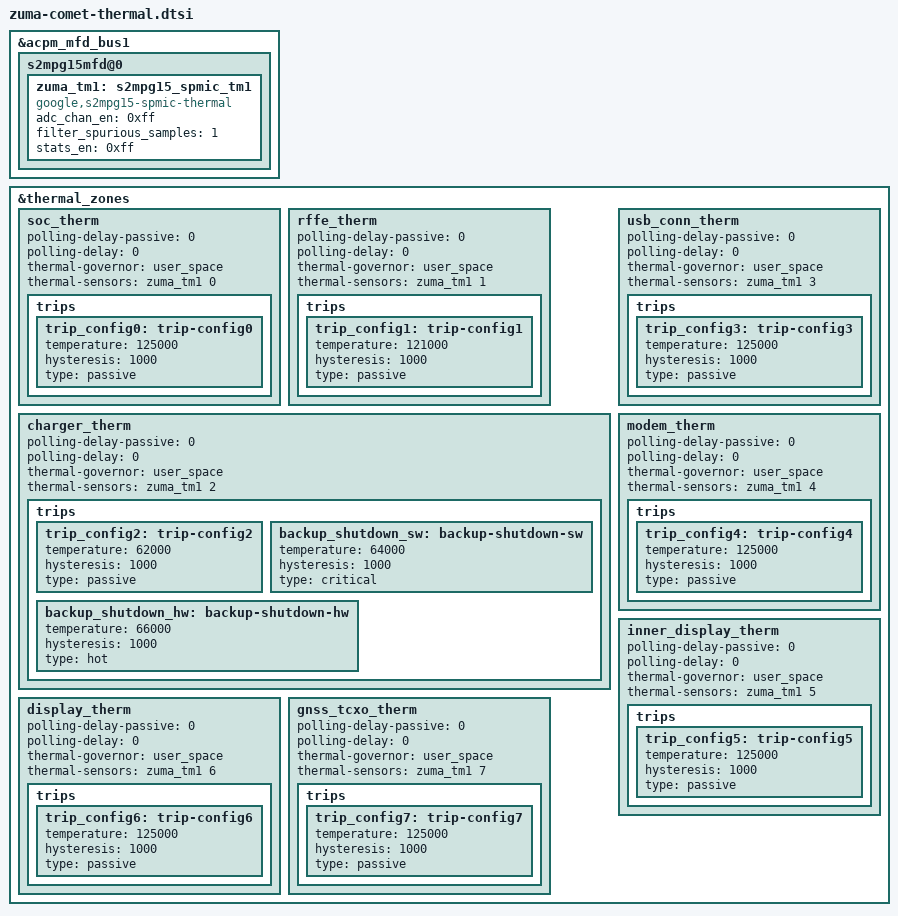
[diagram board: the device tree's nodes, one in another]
// SPDX-License-Identifier: GPL-2.0
/*
 * Google ZUMA comet specific thermal device tree source
 *
 * Copyright (c) 2023 Google, LLC
 *		https://www.google.com
 */

#include <dt-bindings/thermal/thermal.h>

&acpm_mfd_bus1 {
	s2mpg15mfd@0 {
		zuma_tm1: s2mpg15_spmic_tm1 {
			compatible = "google,s2mpg15-spmic-thermal";
			#thermal-sensor-cells = <1>;
			adc_chan_en = /bits/ 8 <0xff>;
			filter_spurious_samples = <1>;
			stats_en = /bits/ 8 <0xff>;
		};
	};
};

/* Thermal Zones */
&thermal_zones {
	soc_therm {
		polling-delay-passive = <0>;
		polling-delay = <0>;
		thermal-governor = "user_space";
		thermal-sensors = <&zuma_tm1 0>;
		trips {
			trip_config0: trip-config0 {
				temperature = <125000>;
				hysteresis = <1000>;
				type = "passive";
			};
		};
	};
	rffe_therm {
		polling-delay-passive = <0>;
		polling-delay = <0>;
		thermal-governor = "user_space";
		thermal-sensors = <&zuma_tm1 1>;
		trips {
			trip_config1: trip-config1 {
				temperature = <121000>;
				hysteresis = <1000>;
				type = "passive";
			};
		};
	};
	charger_therm {
		polling-delay-passive = <0>;
		polling-delay = <0>;
		thermal-governor = "user_space";
		thermal-sensors = <&zuma_tm1 2>;
		trips {
			trip_config2: trip-config2 {
				temperature = <62000>;
				hysteresis = <1000>;
				type = "passive";
			};
			backup_shutdown_sw: backup-shutdown-sw {
				temperature = <64000>;
				hysteresis = <1000>;
				type = "critical";
			};
			backup_shutdown_hw: backup-shutdown-hw {
				temperature = <66000>;
				hysteresis = <1000>;
				type = "hot";
			};
		};
	};
	usb_conn_therm {
		polling-delay-passive = <0>;
		polling-delay = <0>;
		thermal-governor = "user_space";
		thermal-sensors = <&zuma_tm1 3>;
		trips {
			trip_config3: trip-config3 {
				temperature = <125000>;
				hysteresis = <1000>;
				type = "passive";
			};
		};
	};
	modem_therm {
		polling-delay-passive = <0>;
		polling-delay = <0>;
		thermal-governor = "user_space";
		thermal-sensors = <&zuma_tm1 4>;
		trips {
			trip_config4: trip-config4 {
				temperature = <125000>;
				hysteresis = <1000>;
				type = "passive";
			};
		};
	};
	inner_display_therm {
		polling-delay-passive = <0>;
		polling-delay = <0>;
		thermal-governor = "user_space";
		thermal-sensors = <&zuma_tm1 5>;
		trips {
			trip_config5: trip-config5 {
				temperature = <125000>;
				hysteresis = <1000>;
				type = "passive";
			};
		};
	};
	display_therm {
		polling-delay-passive = <0>;
		polling-delay = <0>;
		thermal-governor = "user_space";
		thermal-sensors = <&zuma_tm1 6>;
		trips {
			trip_config6: trip-config6 {
				temperature = <125000>;
				hysteresis = <1000>;
				type = "passive";
			};
		};
	};
	gnss_tcxo_therm {
		polling-delay-passive = <0>;
		polling-delay = <0>;
		thermal-governor = "user_space";
		thermal-sensors = <&zuma_tm1 7>;
		trips {
			trip_config7: trip-config7 {
				temperature = <125000>;
				hysteresis = <1000>;
				type = "passive";
			};
		};
	};
};
